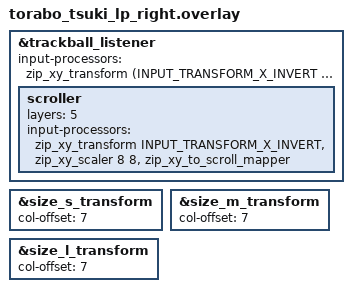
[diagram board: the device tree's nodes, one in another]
#include "torabo_tsuki_lp.dtsi"
#include <input/processors.dtsi>
#include <dt-bindings/zmk/input_transform.h>

&trackball_listener {
    // Default: mouse movement mode
    input-processors = <
        &zip_xy_transform (INPUT_TRANSFORM_X_INVERT | INPUT_TRANSFORM_Y_INVERT)
    >;

    // When layer 5 is active: scroll mode
    scroller {
        layers = <5>;
        input-processors = <
            &zip_xy_transform INPUT_TRANSFORM_X_INVERT
            &zip_xy_scaler 8 8
            &zip_xy_to_scroll_mapper
        >;
    };
};

&size_s_transform {
    col-offset = <7>;
};

&size_m_transform {
    col-offset = <7>;
};

&size_l_transform {
    col-offset = <7>;
};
